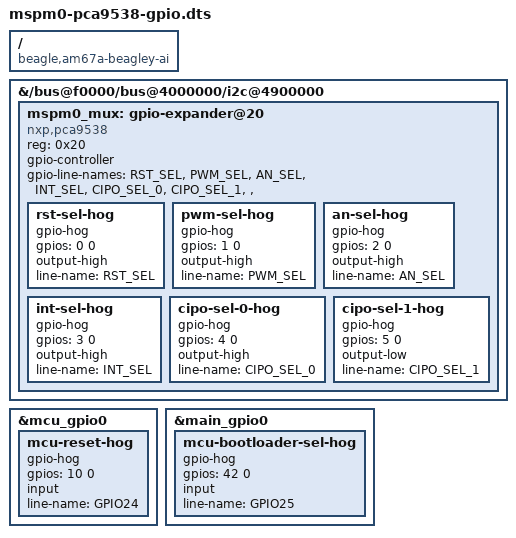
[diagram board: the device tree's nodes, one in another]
/dts-v1/;
/plugin/;

/ {
	compatible = "beagle,am67a-beagley-ai", "ti,am67";

	fragment@0 {
		target-path = "/bus@f0000/bus@4000000/i2c@4900000";
		__overlay__ {
			#address-cells = <1>;
			#size-cells = <0>;

			mspm0_mux: gpio-expander@20 {
				compatible = "nxp,pca9538";
				reg = <0x20>;
				gpio-controller;
				#gpio-cells = <2>;
				gpio-line-names =
					"RST_SEL",
					"PWM_SEL",
					"AN_SEL",
					"INT_SEL",
					"CIPO_SEL_0",
					"CIPO_SEL_1",
					"",
					"";
				status = "okay";

				/* BeagleY-AI / AM67A audio-board routing defaults. */
				rst-sel-hog {
					gpio-hog;
					gpios = <0 0>;
					output-high;
					line-name = "RST_SEL";
				};

				pwm-sel-hog {
					gpio-hog;
					gpios = <1 0>;
					output-high;
					line-name = "PWM_SEL";
				};

				an-sel-hog {
					gpio-hog;
					gpios = <2 0>;
					output-high;
					line-name = "AN_SEL";
				};

				int-sel-hog {
					gpio-hog;
					gpios = <3 0>;
					output-high;
					line-name = "INT_SEL";
				};

				cipo-sel-0-hog {
					gpio-hog;
					gpios = <4 0>;
					output-high;
					line-name = "CIPO_SEL_0";
				};

				cipo-sel-1-hog {
					gpio-hog;
					gpios = <5 0>;
					output-low;
					line-name = "CIPO_SEL_1";
				};
			};
		};
	};

	fragment@1 {
		target = <&mcu_gpio0>;
		__overlay__ {
			status = "okay";

			/* HAT pin 18 / MCU_RESET / GPIO24: C8, MCU_GPIO0_10. */
			mcu-reset-hog {
				gpio-hog;
				gpios = <10 0>;
				input;
				line-name = "GPIO24";
			};
		};
	};

	fragment@2 {
		target = <&main_gpio0>;
		__overlay__ {
			status = "okay";

			/* HAT pin 22 / MCU_BOOTLOADER_SEL / GPIO25: P21, GPIO0_42. */
			mcu-bootloader-sel-hog {
				gpio-hog;
				gpios = <42 0>;
				input;
				line-name = "GPIO25";
			};
		};
	};
};
